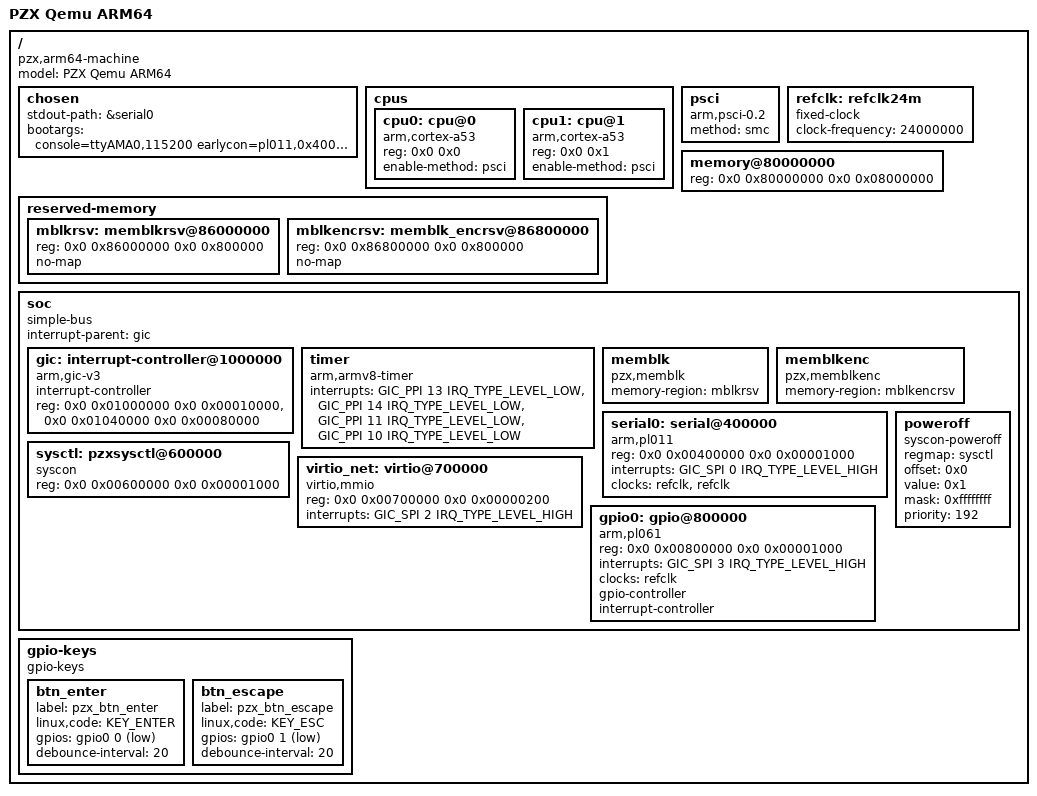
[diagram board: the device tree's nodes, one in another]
// SPDX-License-Identifier: GPL-2.0+

/dts-v1/;

#include <dt-bindings/interrupt-controller/arm-gic.h>
#include <dt-bindings/gpio/gpio.h>
#include <dt-bindings/input/input.h>

/ {
	model = "PZX Qemu ARM64";
	compatible = "pzx,arm64-machine";
	#address-cells = <2>;
	#size-cells = <2>;

	chosen {
		stdout-path = &serial0;
		bootargs = "console=ttyAMA0,115200 earlycon=pl011,0x400000 rdinit=/linuxrc";
	};

	cpus {
		#address-cells = <2>;
		#size-cells = <0>;

		cpu0: cpu@0 {
			device_type = "cpu";
			compatible = "arm,cortex-a53";
			reg = <0x0 0x0>;
			enable-method = "psci";
		};

		cpu1: cpu@1 {
			device_type = "cpu";
			compatible = "arm,cortex-a53";
			reg = <0x0 0x1>;
			enable-method = "psci";
		};
	};

	psci {
    	compatible = "arm,psci-0.2";
    	method = "smc";
	};

	refclk: refclk24m {
		compatible = "fixed-clock";
		#clock-cells = <0>;
		clock-frequency = <24000000>;
	};

	memory@80000000 {
		device_type = "memory";
		reg = <0x0 0x80000000 0x0 0x08000000>; /* 128MB DRAM */
	};

	reserved-memory {
		#address-cells = <2>;
		#size-cells = <2>;
		ranges;

		mblkrsv: memblkrsv@86000000 {
			reg = <0x0 0x86000000 0x0 0x800000>;
			no-map;
		};

		mblkencrsv: memblk_encrsv@86800000 {
			reg = <0x0 0x86800000 0x0 0x800000>;
			no-map;
		};
	};

	soc {
		compatible = "simple-bus";
		#address-cells = <2>;
		#size-cells = <2>;
		ranges;
		interrupt-parent = <&gic>;

		gic: interrupt-controller@1000000 {
			compatible = "arm,gic-v3";
			#interrupt-cells = <3>;
			interrupt-controller;
			reg = <0x0 0x01000000 0x0 0x00010000>, /* GICD */
			      <0x0 0x01040000 0x0 0x00080000>; /* GICR */
		};

		timer {
			compatible = "arm,armv8-timer";
			interrupts = <GIC_PPI 13 IRQ_TYPE_LEVEL_LOW>, <GIC_PPI 14 IRQ_TYPE_LEVEL_LOW>,
					<GIC_PPI 11 IRQ_TYPE_LEVEL_LOW>, <GIC_PPI 10 IRQ_TYPE_LEVEL_LOW>;
		};

		memblk {
			compatible = "pzx,memblk";
			memory-region = <&mblkrsv>;
		};

		memblkenc {
			compatible = "pzx,memblkenc";
			memory-region = <&mblkencrsv>;
		};

		serial0: serial@400000 {
			compatible = "arm,pl011", "arm,primecell";
			reg = <0x0 0x00400000 0x0 0x00001000>;
			interrupts = <GIC_SPI 0 IRQ_TYPE_LEVEL_HIGH>;
			clocks = <&refclk>, <&refclk>;
			clock-names = "uartclk", "apb_pclk";
		};

		sysctl: pzxsysctl@600000 {
			compatible = "syscon", "simple-mfd";
			reg = <0x0 0x00600000 0x0 0x00001000>;
		};

		poweroff {
			compatible = "syscon-poweroff";
			regmap = <&sysctl>;
			offset = <0x0>;
			value = <0x1>;
			mask = <0xffffffff>;
			priority = <192>;
		};

		virtio_net: virtio@700000 {
			compatible = "virtio,mmio";
			reg = <0x0 0x00700000 0x0 0x00000200>;
			interrupts = <GIC_SPI 2 IRQ_TYPE_LEVEL_HIGH>;
		};

		gpio0: gpio@800000 {
			compatible = "arm,pl061", "arm,primecell";
			reg = <0x0 0x00800000 0x0 0x00001000>;
			interrupts = <GIC_SPI 3 IRQ_TYPE_LEVEL_HIGH>;
			clocks = <&refclk>;
			clock-names = "apb_pclk";
			gpio-controller;
			#gpio-cells= <2>;
			interrupt-controller;
			#interrupt-cells = <2>;
		};
	};

	gpio-keys {
		compatible = "gpio-keys";

		btn_enter {
			label = "pzx_btn_enter";
			linux,code = <KEY_ENTER>;
			gpios = <&gpio0 0 GPIO_ACTIVE_LOW>;
			debounce-interval = <20>;
		};

		btn_escape {
			label = "pzx_btn_escape";
			linux,code = <KEY_ESC>;
			gpios = <&gpio0 1 GPIO_ACTIVE_LOW>;
			debounce-interval = <20>;
		};
	};
};
